# CY8C5568AXI_060 register map
File version: 0.1
CY8C55
Registers are 8-bit, read-write, no defined reset value unless marked. A register's access mark holds for its fields unless they carry their own. Offsets are from the block's base; lines under a group give offsets from that group; [hi:lo] are bit positions; {n}, {i} and the like mark numbered series; 'fields as' and 'values as' point back to an identical list; <NAME> marks a mode.

## Memory map
0x400043A3 Motor_1_Timer_1 size 0xB62
0x40006421 Motor_1_PWM_15 size 0x71
0x40006422 Motor_1_PWM_5 size 0x71
0x40006423 Motor_1_PWM_16 size 0x71
0x40006424 Motor_1_PWM_8 size 0x71
0x40006425 Motor_1_PWM_1 size 0x71
0x40006426 Motor_1_PWM_10 size 0x151
0x40006428 Motor_1_PWM_11 size 0x71
0x40006429 Motor_1_PWM_14 size 0x71
0x4000642B Motor_1_PWM_7 size 0x71
0x4000646F Motor_1_Status_Reg_1 size 0x31
0x40006476 Motor_1_PWM_4 size 0x121
0x40006477 Motor_1_Control_Reg_1 size 0x1
0x40006524 Motor_1_PWM_9 size 0x71
0x40006525 Motor_1_PWM_6 size 0x71
0x40006527 Motor_1_PWM_2 size 0x71
0x40006528 Motor_1_PWM_12 size 0x71
0x40006529 Motor_1_PWM_13 size 0x71
0x4000652B Motor_1_PWM_3 size 0x71

## Motor_1_Control_Reg_1
Base 0x40006477
0x00 Motor_1_Control_Reg_1_CONTROL_REG

## Motor_1_Timer_1
Base 0x400043A3
0x00 Motor_1_Timer_1_GLOBAL_ENABLE — PM.ACT.CFG
  [3:0] en_timer — Enable timer/counters.
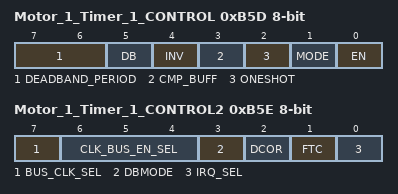
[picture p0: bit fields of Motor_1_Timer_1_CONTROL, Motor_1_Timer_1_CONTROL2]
0xB5D Motor_1_Timer_1_CONTROL — TMRx.CFG0
  [7:6] DEADBAND_PERIOD
  [5] DB — Deadband mode--Deadband phases phi1 and phi2 are outputted on CMP and TC output pins respectively.
    0=Timer (CMP and TC are output.); 1=Deadband (PHI1 (instead of CMP) and PHI2 (instead of TC) are output.)
  [4] INV — Invert sense of TIMEREN signal
  [3] CMP_BUFF — Buffer compare register. Compare register updates only on timer terminal count.
  [2] ONESHOT — Timer stops upon reaching stop condition defined by TMR_CFG bits. Can be restarted by asserting TIMER RESET or disabling and re-enabling block.
  [1] MODE — Mode. (0 = Timer; 1 = Comparator)
    0=Timer mode. CNT/CMP register holds timer count value.; 1=Comparator mode. CNT/CMP register holds comparator threshold value.
  [0] EN — Enables timer/comparator.
0xB5E Motor_1_Timer_1_CONTROL2 — TMRx.CFG1
  [7] BUS_CLK_SEL — Bus Clock selection.
  [6:4] CLK_BUS_EN_SEL — Digital Global Clock selection.
  [3] DBMODE — Deadband mode (asynchronous/synchronous). CMP output pin is also affected when not in deadband mode (CFG0.DEADBAND).
  [2] DCOR — Disable Clear on Read (DCOR) of Status Register SR0.
  [1] FTC — First Terminal Count (FTC). Setting this bit forces a single pulse on the TC pin when first enabled.
    0=Disable_FTC (Disable the single cycle pulse, which signifies the timer is starting.); 1=Enable_FTC (Enable the single cycle pulse, which signifies the timer is starting.)
  [0] IRQ_SEL — Irq selection. (0 = raw interrupts; 1 = status register interrupts)
0xB5F Motor_1_Timer_1_PERIOD — TMRx.PER0 - Assigned Period
0xB61 Motor_1_Timer_1_COUNTER — TMRx.CNT_CMP0 - Current Down Counter Value

## Motor_1_Status_Reg_1
Base 0x4000646F
0x00 Motor_1_Status_Reg_1_STATUS_REG
0x20 Motor_1_Status_Reg_1_MASK_REG
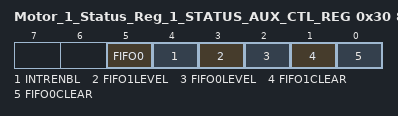
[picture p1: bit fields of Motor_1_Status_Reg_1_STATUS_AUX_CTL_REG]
0x30 Motor_1_Status_Reg_1_STATUS_AUX_CTL_REG
  [5] FIFO0 — FIFO0 clear
    1=ENABLED (Enable counter); 0=DISABLED (Disable counter)
  [4] INTRENBL — Enables or disables the Interrupt
    1=ENABLED (Interrupt enabled); 0=DISABLED (Interrupt disabled)
  [3] FIFO1LEVEL — FIFO level
    1=ENABLED (FIFO LVL: input mode: FIFO at least 1/2 empty; output mode: FIFO at least 1/2 full); 0=DISABLED (FIFO LVL: input mode: FIFO not full; output mode: FIFO not empty)
  [2] FIFO0LEVEL — FIFO level
    values as FIFO1LEVEL
  [1] FIFO1CLEAR — FIFO clear
    1=ENABLED (Clear FIFO state); 0=DISABLED (Normal FIFO operation)
  [0] FIFO0CLEAR — FIFO clear
    values as FIFO1CLEAR

## Motor_1_PWM_4
Base 0x40006476
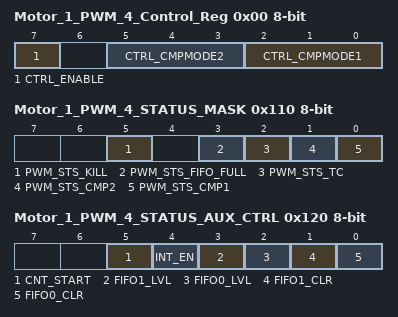
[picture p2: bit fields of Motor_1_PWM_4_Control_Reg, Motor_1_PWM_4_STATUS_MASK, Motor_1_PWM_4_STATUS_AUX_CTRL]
0x00 Motor_1_PWM_4_Control_Reg — UDB Control Register - Assigned Control Register Value
  [7] CTRL_ENABLE — Enable the PWM
  [5:3] CTRL_CMPMODE2 — Compare mode 2
  [2:0] CTRL_CMPMODE1 — Compare mode 1
0xB0 Motor_1_PWM_4_COMPARE_Reg_ — UDB.D0 - Assigned Compare Value
0x110 Motor_1_PWM_4_STATUS_MASK — UDB Status bits Interrupt Mask Enable Register
  [5] PWM_STS_KILL ro — Enables the Interrupt on Kill
  [3] PWM_STS_FIFO_FULL ro — FIFO Full Status Mask
  [2] PWM_STS_TC ro — Enables the Interrupt on Terminal Count
  [1] PWM_STS_CMP2 ro — Enables the Interrupt on Compare 2
  [0] PWM_STS_CMP1 ro — Enables the Interrupt on Compare 1
0x120 Motor_1_PWM_4_STATUS_AUX_CTRL — UDB Auxilliary Control Register
  [5] CNT_START — FIFO0 clear
    0=E_CNT_START0 (Disable counter); 1=E_CNT_START1 (Enable counter)
  [4] INT_EN
    0=E_INT_EN0 (Interrupt disabled); 1=E_INT_EN1 (Interrupt enabled)
  [3] FIFO1_LVL — FIFO level
    0=E_FIFO_LVL_0 (FIFO LVL: input mode: FIFO not full; output mode: FIFO not empty); 1=E_FIFO_LVL_1 (FIFO LVL: input mode: FIFO at least 1/2 empty; output mode: FIFO at least 1/2 full)
  [2] FIFO0_LVL — FIFO level
    values as FIFO1_LVL
  [1] FIFO1_CLR — FIFO1 clear
    0=E_FIFO_CLR_0 (Normal FIFO operation); 1=E_FIFO_CLR_1 (Clear FIFO state)
  [0] FIFO0_CLR — FIFO0 clear
    values as FIFO1_CLR
